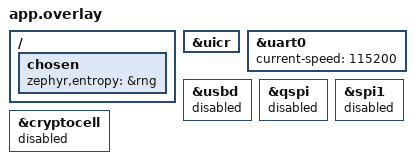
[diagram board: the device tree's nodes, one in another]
/* SPDX-License-Identifier: BSD-3-Clause */
/ {
    chosen {
        zephyr,entropy = &rng;
    };
};

&uicr {
    /delete-property/ gpio-as-nreset;
    /delete-property/ nfct-pins-as-gpios;
};

&uart0 {
    status = "okay";
    current-speed = <115200>;
    /delete-property/ hw-flow-control;
};

&usbd { status = "disabled"; };
&qspi { status = "disabled"; };
&spi1 { status = "disabled"; };
&cryptocell { status = "disabled"; };
